# IPU_PRM register map
Vendor: Texas Instruments
Peripheral module from a debugger description file (folder am571x).
Registers are 32-bit, access per field, reset 0x0 unless marked. A register's access mark holds for its fields unless they carry their own. Offsets are as the file gives them; lines under a group give offsets from that group; [hi:lo] are bit positions; {n}, {i} and the like mark numbered series; 'fields as' and 'values as' point back to an identical list; <NAME> marks a mode.

## IPU_PRM
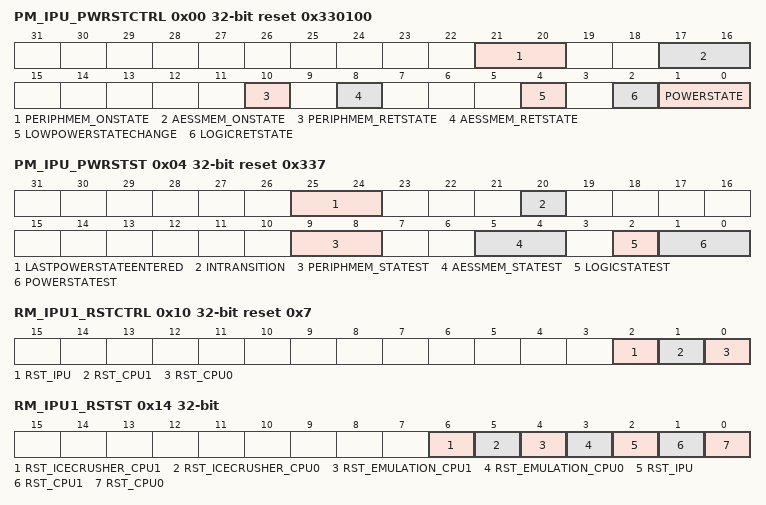
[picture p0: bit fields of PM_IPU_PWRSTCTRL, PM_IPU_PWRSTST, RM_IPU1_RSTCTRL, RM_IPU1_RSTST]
0x00 PM_IPU_PWRSTCTRL reset 0x330100 — This register controls the IPU domain power state to reach upon a domain sleep transition
  [21:20] PERIPHMEM_ONSTATE ro — PERIPHMEM memory state when domain is ON.
    3=MEM_ON (Memory bank is on when the domain is ON.)
  [17:16] AESSMEM_ONSTATE ro — AESSMEM memory state when domain is ON.
    3=MEM_ON (Memory bank is on when the domain is ON.)
  [10] PERIPHMEM_RETSTATE rw — PERIPHMEM memory state when domain is RETENTION.
    0=MEM_OFF (Memory bank is off when the domain is in the RETENTION state.); 1=MEM_RET (Memory bank is retained when domain is in RETENTION state.)
  [8] AESSMEM_RETSTATE rw — AESSMEM memory state when domain is RETENTION.
    values as PERIPHMEM_RETSTATE
  [4] LOWPOWERSTATECHANGE rw — Power state change request when domain has already performed a sleep transition. Allows going into deeper low power state without waking up the power domain.
    0=DIS (Do not request a low power state change.); 1=EN (Request a low power state change. This bit is automatically cleared when the power state is effectively changed or when power state is ON.)
  [2] LOGICRETSTATE ro — Logic state when power domain is RETENTION
    0=LOGIC_OFF (Whole logic is off when the domain is in RETENTION state.)
  [1:0] POWERSTATE rw — Power state control
    0=OFF (OFF state); 1=RET (RETENTION state); 2=INACT (INACTIVE state); 3=ON (ON State)
0x04 PM_IPU_PWRSTST reset 0x337 — This register provides a status on the IPU domain current power domain state. [warm reset insensitive]
  [25:24] LASTPOWERSTATEENTERED rw — Last low power state entered. Set to 0x3 upon write of the same only. This register is intended for debug purpose only.
    0=OFF (Power domain was previously OFF); 1=RET (Power domain was previously in RETENTION); 2=INACTIVE (Power domain was previously ON-INACTIVE); 3=ON (Power domain was previously ON-ACTIVE)
  [20] INTRANSITION ro — Domain transition status
    0=NO (No on-going transition on power domain); 1=ONGOING (Power domain transition is in progress.)
  [9:8] PERIPHMEM_STATEST ro — PERIPHMEM memory state status
    0=MEM_OFF (Memory is OFF); 3=MEM_ON (Memory is ON)
  [5:4] AESSMEM_STATEST ro — AESSMEM memory state status
    0=MEM_OFF (Memory is OFF); 1=MEM_RET (Memory is RETENTION); 3=MEM_ON (Memory is ON)
  [2] LOGICSTATEST ro — Logic state status
    0=OFF (Logic in domain is OFF); 1=ON (Logic in domain is ON)
  [1:0] POWERSTATEST ro — Current power state status
    0=OFF (Power domain is OFF); 1=RET (Power domain is in RETENTION); 2=INACTIVE (Power domain is ON-INACTIVE); 3=ON (Power domain is ON-ACTIVE)
0x10 RM_IPU1_RSTCTRL reset 0x7 — This register controls the release of the IPU1 sub-system resets.
  [2] RST_IPU rw — IPU system reset control.
    0=CLEAR (Reset is cleared for IPU CACHE MMU); 1=ASSERT (Reset is asserted for the IPU CACHE MMU)
  [1] RST_CPU1 rw — IPU Cortex M4 CPU1 reset control
    0=CLEAR (Reset is cleared for the IPU Cortex M4 CPU1); 1=ASSERT (Reset is asserted for the IPU Cortex M4 CPU1)
  [0] RST_CPU0 rw — IPU Cortex M4 CPU0 reset control.
    0=CLEAR (Reset is cleared for the IPU Cortex M4 CPU0); 1=ASSERT (Reset is asserted for the IPU Cortex M4 CPU0)
0x14 RM_IPU1_RSTST — This register logs the different reset sources of the IPU1 SS. Each bit is set upon release of the domain reset signal. Must be cleared by software. [warm reset insensitive]
  [6] RST_ICECRUSHER_CPU1 rw — Cortex M4 CPU1 has been reset due to IPU ICECRUSHER1 reset source
    0=RESET_NO (No icecrusher reset); 1=RESET_YES (CPU1 has been reset upon icecrusher reset)
  [5] RST_ICECRUSHER_CPU0 rw — Cortex M4 CPU0 has been reset due to IPU ICECRUSHER0 reset source
    0=RESET_NO (No icecrusher reset); 1=RESET_YES (CPU0 has been reset upon icecrusher reset)
  [4] RST_EMULATION_CPU1 rw — Cortex M4 CPU1 has been reset due to emulation reset source e.g. assert reset command initiated by the icepick module
    0=RESET_NO (No emulation reset); 1=RESET_YES (CPU1 has been reset upon emulation reset)
  [3] RST_EMULATION_CPU0 rw — Cortex M4 CPU0 has been reset due to emulation reset source e.g. assert reset command initiated by the icepick module
    0=RESET_NO (No emulation reset); 1=RESET_YES (CPU0 has been reset upon emulation reset)
  [2] RST_IPU rw — IPU system SW reset status
    0=RESET_NO (No SW reset occurred); 1=RESET_YES (IPU MMU and CACHE interface has been reset upon SW reset)
  [1] RST_CPU1 rw — IPU Cortex-M4 CPU1 SW reset status
    0=RESET_NO (No SW reset occurred); 1=RESET_YES (Cortex M4 CPU1 has been reset upon SW reset)
  [0] RST_CPU0 rw — IPU Cortex-M4 CPU0 SW reset status
    0=RESET_NO (No SW reset occurred); 1=RESET_YES (Cortex M4 CPU0 has been reset upon SW reset)
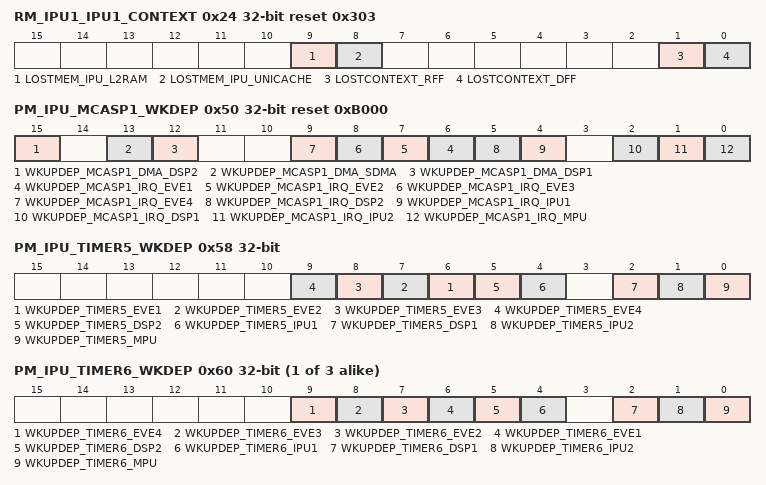
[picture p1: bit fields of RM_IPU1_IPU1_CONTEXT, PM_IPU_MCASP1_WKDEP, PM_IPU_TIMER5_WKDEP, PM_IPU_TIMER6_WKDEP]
0x24 RM_IPU1_IPU1_CONTEXT reset 0x303 — This register contains dedicated IPU1 context statuses. [warm reset insensitive]
  [all] fields
    0=MAINTAINED (Context has been maintained); 1=LOST (Context has been lost)
  [9] LOSTMEM_IPU_L2RAM rw — Specify if memory-based context in IPU_L2RAM memory bank has been lost due to a previous power transition or other reset source.
  [8] LOSTMEM_IPU_UNICACHE rw — Specify if memory-based context in IPU_UNICACHE memory bank has been lost due to a previous power transition or other reset source.
  [1] LOSTCONTEXT_RFF rw — Specify if RFF-based context has been lost due to a previous power transition or other reset source. (set upon assertion of IPU_RET_RST signal)
  [0] LOSTCONTEXT_DFF rw — Specify if DFF-based context has been lost due to a previous power transition or other reset source. (set upon assertion of IPU_RST signal)
0x50 PM_IPU_MCASP1_WKDEP reset 0xB000 — This register controls wakeup dependency based on MCASP1 service requests.
  [all] fields
    0=DISABLED (Dependency is disabled); 1=ENABLED (Dependency is enabled)
  [15] WKUPDEP_MCASP1_DMA_DSP2 rw — Wakeup dependency from MCASP1 module (SWakeup_dma signal) towards DSP2 + L3_MAIN1 + L4PER1 + L4PER2 + L4PER3 domains
  [13] WKUPDEP_MCASP1_DMA_SDMA rw — Wakeup dependency from MCASP1 module (SWakeup_dma signal) towards SDMA + L3MAIN1 + L4PER1 + L4PER2 + L4PER3 domains
  [12] WKUPDEP_MCASP1_DMA_DSP1 rw — Wakeup dependency from MCASP1 module (SWakeup_dma signal) towards DSP + L3MAIN1 + L4PER1 + L4PER2 + L4PER3 domains
  [n+5] WKUPDEP_MCASP1_IRQ_EVE{n} rw (n=1..4) — Wakeup dependency from MCASP1 module (SWakeup IRQ signal) towards EVE{n} + L3_MAIN1 + L4PER1 + L4PER2 + L4PER3 domains
  [5] WKUPDEP_MCASP1_IRQ_DSP2 rw — Wakeup dependency from MCASP1 module (SWakeup IRQ signal) towards DSP2 + L3_MAIN1 + L4PER1 + L4PER2 + L4PER3 domains
  [4] WKUPDEP_MCASP1_IRQ_IPU1 rw — Wakeup dependency from MCASP1 module (SWakeup IRQ signal) towards IPU1 + L3_MAIN1 + L4PER1 + L4PER2 + L4PER3 domains
  [2] WKUPDEP_MCASP1_IRQ_DSP1 rw — Wakeup dependency from MCASP1 module (SWakeup IRQ signal) towards DSP + L3MAIN1 + L4PER1 + L4PER2 + L4PER3 domains
  [1] WKUPDEP_MCASP1_IRQ_IPU2 rw — Wakeup dependency from MCASP1 module (SWakeup IRQ signal) towards IPU2 + L3_MAIN1 + L4PER1 + L4PER2 + L4PER3 domains
  [0] WKUPDEP_MCASP1_IRQ_MPU rw — Wakeup dependency from MCASP1 module (SWakeup IRQ signal) towards MPU + L3_MAIN1 + L4PER1 + L4PER2 + L4PER3 domains
0x54 RM_IPU_MCASP1_CONTEXT reset 0x1 — This register contains dedicated MCASP context statuses. [warm reset insensitive]
  [0] LOSTCONTEXT_DFF rw — Specify if DFF-based context has been lost due to a previous power transition or other reset source. (set upon assertion of ABE_RST signal)
    values as the fields of RM_IPU1_IPU1_CONTEXT
0x58 PM_IPU_TIMER5_WKDEP — This register controls wakeup dependency based on TIMER5 service requests.
  [all] fields
    values as the fields of PM_IPU_MCASP1_WKDEP
  [n+5] WKUPDEP_TIMER5_EVE{n} rw (n=1..4) — Wakeup dependency from TIMER5 module (SWakeup signal) towards EVE{n} + L3_MAIN1 + L4PER1 + L4PER2 + L4PER3 domains
  [5] WKUPDEP_TIMER5_DSP2 rw — Wakeup dependency from TIMER5 module (SWakeup signal) towards DSP2 + L3_MAIN1 + L4PER1 + L4PER2 + L4PER3 domains
  [4] WKUPDEP_TIMER5_IPU1 rw — Wakeup dependency from TIMER5 module (SWakeup signal) towards IPU1 + L3_MAIN1 + L4PER1 + L4PER2 + L4PER3 domains
  [2] WKUPDEP_TIMER5_DSP1 rw — Wakeup dependency from TIMER5 module (SWakeup signal) towards DSP + L3MAIN1 + L4PER1 + L4PER2 + L4PER3 domains
  [1] WKUPDEP_TIMER5_IPU2 rw — Wakeup dependency from TIMER5 module (SWakeup signal) towards IPU2 + L3_MAIN1 + L4PER1 + L4PER2 + L4PER3 domains
  [0] WKUPDEP_TIMER5_MPU rw — Wakeup dependency from TIMER5 module (SWakeup signal) towards MPU + L3_MAIN1 + L4PER1 + L4PER2 + L4PER3 domains
{0x34+8i} RM_IPU_TIMER{i}_CONTEXT reset 0x1 (i=5..8) — This register contains dedicated TIMER{i} context statuses. [warm reset insensitive]
  fields as RM_IPU_MCASP1_CONTEXT
{0x30+8i} PM_IPU_TIMER{i}_WKDEP (i=6..8) — This register controls wakeup dependency based on TIMER{i} service requests.
  [all] fields
    values as the fields of PM_IPU_MCASP1_WKDEP
  [9] WKUPDEP_TIMER{i}_EVE4 rw — Wakeup dependency from TIMER{i} module (SWakeup signal) towards EVE4 + L3_MAIN1 + L4PER1 + L4PER2 + L4PER3 domains
  [8] WKUPDEP_TIMER{i}_EVE3 rw — Wakeup dependency from TIMER{i} (SWakeup signal) towards EVE3 + L3_MAIN1 + L4PER1 + L4PER2 + L4PER3 domains
  [7] WKUPDEP_TIMER{i}_EVE2 rw — Wakeup dependency from TIMER{i} module (SWakeup signal) towards EVE2 + L3_MAIN1 + L4PER1 + L4PER2 + L4PER3 domains
  [6] WKUPDEP_TIMER{i}_EVE1 rw — Wakeup dependency from TIMER{i} module (SWakeup signal) towards EVE1 + L3_MAIN1 + L4PER1 + L4PER2 + L4PER3 domains
  [5] WKUPDEP_TIMER{i}_DSP2 rw — Wakeup dependency from TIMER{i} module (SWakeup signal) towards DSP2 + L3_MAIN1 + L4PER1 + L4PER2 + L4PER3 domains
  [4] WKUPDEP_TIMER{i}_IPU1 rw — Wakeup dependency from TIMER{i} module (SWakeup signal) towards IPU1 + L3_MAIN1 + L4PER1 + L4PER2 + L4PER3 domains
  [2] WKUPDEP_TIMER{i}_DSP1 rw — Wakeup dependency from TIMER{i} module (SWakeup signal) towards DSP + L3MAIN1 + L4PER1 + L4PER2 + L4PER3 domains
  [1] WKUPDEP_TIMER{i}_IPU2 rw — Wakeup dependency from TIMER{i} module (SWakeup signal) towards IPU2 + L3_MAIN1 + L4PER1 + L4PER2 + L4PER3 domains
  [0] WKUPDEP_TIMER{i}_MPU rw — Wakeup dependency from TIMER{i} module (SWakeup signal) towards MPU + L3_MAIN1 + L4PER1 + L4PER2 + L4PER3 domains
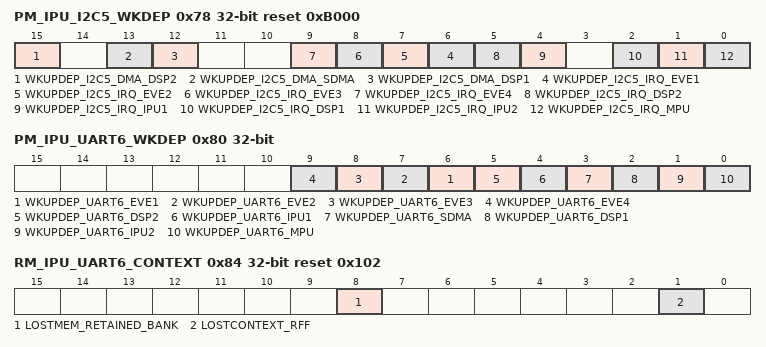
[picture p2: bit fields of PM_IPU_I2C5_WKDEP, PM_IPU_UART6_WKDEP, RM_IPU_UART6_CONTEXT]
0x78 PM_IPU_I2C5_WKDEP reset 0xB000 — This register controls wakeup dependency based on I2C5 service requests.
  [all] fields
    values as the fields of PM_IPU_MCASP1_WKDEP
  [15] WKUPDEP_I2C5_DMA_DSP2 rw — Wakeup dependency from I2C5 module (SWakeup_dma signal) towards DSP2 + L3_MAIN1 + L4PER1 + L4PER2 + L4PER3 domains
  [13] WKUPDEP_I2C5_DMA_SDMA rw — Wakeup dependency from I2C5 module (SWakeup_dma signal) towards SDMA + L3MAIN1 + L4PER1 + L4PER2 + L4PER3 domains
  [12] WKUPDEP_I2C5_DMA_DSP1 rw — Wakeup dependency from I2C5 module (SWakeup_dma signal) towards DSP + L3MAIN1 + L4PER1 + L4PER2 + L4PER3 domains
  [n+5] WKUPDEP_I2C5_IRQ_EVE{n} rw (n=1..4) — Wakeup dependency from I2C5 module (SWakeup IRQ signal) towards EVE{n} + L3_MAIN1 + L4PER1 + L4PER2 + L4PER3 domains
  [5] WKUPDEP_I2C5_IRQ_DSP2 rw — Wakeup dependency from I2C5 module (SWakeup IRQ signal) towards DSP2 + L3_MAIN1 + L4PER1 + L4PER2 + L4PER3 domains
  [4] WKUPDEP_I2C5_IRQ_IPU1 rw — Wakeup dependency from I2C5 module (SWakeup IRQ signal) towards IPU1 + L3_MAIN1 + L4PER1 + L4PER2 + L4PER3 domains
  [2] WKUPDEP_I2C5_IRQ_DSP1 rw — Wakeup dependency from I2C5 module (SWakeup IRQ signal) towards DSP + L3MAIN1 + L4PER1 + L4PER2 + L4PER3 domains
  [1] WKUPDEP_I2C5_IRQ_IPU2 rw — Wakeup dependency from I2C5 module (SWakeup IRQ signal) towards IPU2 + L3_MAIN1 + L4PER1 + L4PER2 + L4PER3 domains
  [0] WKUPDEP_I2C5_IRQ_MPU rw — Wakeup dependency from I2C5 module (SWakeup IRQ signal) towards MPU + L3_MAIN1 + L4PER1 + L4PER2 + L4PER3 domains
0x7C RM_IPU_I2C5_CONTEXT reset 0x1 — This register contains dedicated I2C5 context statuses. [warm reset insensitive]
  [0] LOSTCONTEXT_DFF rw — Specify if DFF-based context has been lost due to a previous power transition or other reset source. (set upon assertion of L4PER_RST signal)
    values as the fields of RM_IPU1_IPU1_CONTEXT
0x80 PM_IPU_UART6_WKDEP — This register controls wakeup dependency based on UART6 service requests.
  [all] fields
    values as the fields of PM_IPU_MCASP1_WKDEP
  [n+5] WKUPDEP_UART6_EVE{n} rw (n=1..4) — Wakeup dependency from UART6 module (SWakeup signal) towards EVE{n} + L3_MAIN1 + L4PER1 + L4PER2 + L4PER3 domains
  [5] WKUPDEP_UART6_DSP2 rw — Wakeup dependency from UART6 module (SWakeup signal) towards DSP2 + L3_MAIN1 + L4PER1 + L4PER2 + L4PER3 domains
  [4] WKUPDEP_UART6_IPU1 rw — Wakeup dependency from UART6 module (SWakeup signal) towards IPU1 + L3_MAIN1 + L4PER1 + L4PER2 + L4PER3 domains
  [3] WKUPDEP_UART6_SDMA rw — Wakeup dependency from UART6 module (SWakeup signal) towards SDMA + L3MAIN1 + L4PER1 + L4PER2 + L4PER3 domains
  [2] WKUPDEP_UART6_DSP1 rw — Wakeup dependency from UART6 module (SWakeup signal) towards DSP + L3MAIN1 + L4PER1 + L4PER2 + L4PER3 domains
  [1] WKUPDEP_UART6_IPU2 rw — Wakeup dependency from UART6 module (SWakeup signal) towards IPU2 + L3_MAIN1 + L4PER1 + L4PER2 + L4PER3 domains
  [0] WKUPDEP_UART6_MPU rw — Wakeup dependency from UART6 module (SWakeup signal) towards MPU + L3_MAIN1 + L4PER1 + L4PER2 + L4PER3 domains
0x84 RM_IPU_UART6_CONTEXT reset 0x102 — This register contains dedicated UART6 context statuses. [warm reset insensitive]
  [8] LOSTMEM_RETAINED_BANK rw — Specify if memory-based context in RETAINED_BANK memory bank has been lost due to a previous power transition or other reset source.
    values as the fields of RM_IPU1_IPU1_CONTEXT
  [1] LOSTCONTEXT_RFF rw — Specify if DFF-based context has been lost due to a previous power transition or other reset source. (set upon assertion of L4PER_RST signal)
    values as the fields of RM_IPU1_IPU1_CONTEXT
